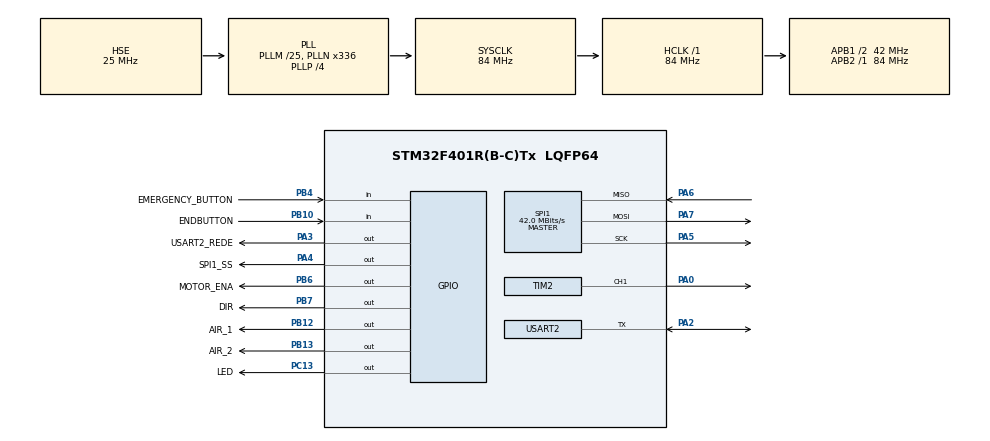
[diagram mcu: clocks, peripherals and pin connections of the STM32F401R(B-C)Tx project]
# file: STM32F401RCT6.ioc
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Dma.Request0=SPI1_RX
Dma.Request1=SPI1_TX
Dma.Request2=USART2_RX
Dma.Request3=USART2_TX
Dma.SPI1_RX.0.Direction=DMA_PERIPH_TO_MEMORY
Dma.SPI1_RX.0.FIFOMode=DMA_FIFOMODE_DISABLE
Dma.SPI1_RX.0.Instance=DMA2_Stream0
Dma.SPI1_RX.0.MemDataAlignment=DMA_MDATAALIGN_BYTE
Dma.SPI1_RX.0.MemInc=DMA_MINC_ENABLE
Dma.SPI1_RX.0.Mode=DMA_NORMAL
Dma.SPI1_RX.0.PeriphDataAlignment=DMA_PDATAALIGN_BYTE
Dma.SPI1_RX.0.PeriphInc=DMA_PINC_DISABLE
Dma.SPI1_RX.0.Priority=DMA_PRIORITY_LOW
Dma.SPI1_TX.1.Direction=DMA_MEMORY_TO_PERIPH
Dma.SPI1_TX.1.FIFOMode=DMA_FIFOMODE_DISABLE
Dma.SPI1_TX.1.Instance=DMA2_Stream3
Dma.SPI1_TX.1.MemDataAlignment=DMA_MDATAALIGN_BYTE
Dma.SPI1_TX.1.MemInc=DMA_MINC_ENABLE
Dma.SPI1_TX.1.Mode=DMA_NORMAL
Dma.SPI1_TX.1.PeriphDataAlignment=DMA_PDATAALIGN_BYTE
Dma.SPI1_TX.1.PeriphInc=DMA_PINC_DISABLE
Dma.SPI1_TX.1.Priority=DMA_PRIORITY_LOW
Dma.USART2_RX.2.Direction=DMA_PERIPH_TO_MEMORY
Dma.USART2_RX.2.FIFOMode=DMA_FIFOMODE_DISABLE
Dma.USART2_RX.2.Instance=DMA1_Stream5
Dma.USART2_RX.2.MemDataAlignment=DMA_MDATAALIGN_BYTE
Dma.USART2_RX.2.MemInc=DMA_MINC_ENABLE
Dma.USART2_RX.2.Mode=DMA_NORMAL
Dma.USART2_RX.2.PeriphDataAlignment=DMA_PDATAALIGN_BYTE
Dma.USART2_RX.2.PeriphInc=DMA_PINC_DISABLE
Dma.USART2_RX.2.Priority=DMA_PRIORITY_LOW
Dma.USART2_TX.3.Direction=DMA_MEMORY_TO_PERIPH
Dma.USART2_TX.3.FIFOMode=DMA_FIFOMODE_DISABLE
Dma.USART2_TX.3.Instance=DMA1_Stream6
Dma.USART2_TX.3.MemDataAlignment=DMA_MDATAALIGN_BYTE
Dma.USART2_TX.3.MemInc=DMA_MINC_ENABLE
Dma.USART2_TX.3.Mode=DMA_NORMAL
Dma.USART2_TX.3.PeriphDataAlignment=DMA_PDATAALIGN_BYTE
Dma.USART2_TX.3.PeriphInc=DMA_PINC_DISABLE
Dma.USART2_TX.3.Priority=DMA_PRIORITY_LOW
FREERTOS.HEAP_NUMBER=1
FREERTOS.Tasks01=defaultTask,24,128,StartCommTask,As weak,NULL,Dynamic,NULL,NULL
FREERTOS.configENABLE_FPU=1
Mcu.Family=STM32F4
Mcu.Name=STM32F401R(B-C)Tx
Mcu.Package=LQFP64
NVIC.DMA1_Stream5_IRQn=true\:5\:0\:false\:false\:true\:true\:false\:true\:true
NVIC.DMA1_Stream6_IRQn=true\:5\:0\:false\:false\:true\:true\:false\:true\:true
NVIC.DMA2_Stream0_IRQn=true\:5\:0\:false\:false\:true\:true\:false\:true\:true
NVIC.DMA2_Stream3_IRQn=true\:5\:0\:false\:false\:true\:true\:false\:true\:true
NVIC.PriorityGroup=NVIC_PRIORITYGROUP_4
NVIC.TIM1_BRK_TIM9_IRQn=true\:5\:0\:false\:false\:true\:true\:true\:true\:true
NVIC.TIM1_TRG_COM_TIM11_IRQn=true\:15\:0\:false\:false\:true\:false\:false\:true\:true
NVIC.TimeBase=TIM1_TRG_COM_TIM11_IRQn
NVIC.TimeBaseIP=TIM11
NVIC.USART2_IRQn=true\:5\:0\:false\:false\:true\:true\:true\:true\:true
PA0-WKUP.GPIO_ModeDefaultPP=GPIO_MODE_AF_OD
PA0-WKUP.GPIO_Speed=GPIO_SPEED_FREQ_VERY_HIGH
PA0-WKUP.Signal=S_TIM2_CH1_ETR
PA13.Mode=Trace_Asynchronous_SW
PA13.Signal=SYS_JTMS-SWDIO
PA14.Mode=Trace_Asynchronous_SW
PA14.Signal=SYS_JTCK-SWCLK
PA2.GPIO_PuPd=GPIO_PULLUP
PA2.Mode=Half_duplex(single_wire_mode)
PA2.Signal=USART2_TX
PA3.GPIO_Label=USART2_REDE
PA3.Signal=GPIO_Output
PA4.GPIO_Label=SPI1_SS
PA4.Signal=GPIO_Output
PA5.Mode=Full_Duplex_Master
PA5.Signal=SPI1_SCK
PA6.Mode=Full_Duplex_Master
PA6.Signal=SPI1_MISO
PA7.Mode=Full_Duplex_Master
PA7.Signal=SPI1_MOSI
PB10.GPIO_Label=ENDBUTTON
PB10.Signal=GPIO_Input
PB12.GPIO_Label=AIR_1
PB12.Signal=GPIO_Output
PB13.GPIO_Label=AIR_2
PB13.Signal=GPIO_Output
PB3.Mode=Trace_Asynchronous_SW
PB3.Signal=SYS_JTDO-SWO
PB4.GPIO_Label=EMERGENCY_BUTTON
PB4.Signal=GPIO_Input
PB6.GPIO_Label=MOTOR_ENA
PB6.GPIO_ModeDefaultOutputPP=GPIO_MODE_OUTPUT_OD
PB6.GPIO_PuPd=GPIO_NOPULL
PB6.Signal=GPIO_Output
PB7.GPIO_Label=DIR
PB7.GPIO_ModeDefaultOutputPP=GPIO_MODE_OUTPUT_OD
PB7.GPIO_PuPd=GPIO_NOPULL
PB7.Signal=GPIO_Output
PC13-ANTI_TAMP.GPIO_Label=LED
PC13-ANTI_TAMP.PinState=GPIO_PIN_RESET
PC13-ANTI_TAMP.Signal=GPIO_Output
PC14-OSC32_IN.Mode=LSE-External-Oscillator
PC14-OSC32_IN.Signal=RCC_OSC32_IN
PC15-OSC32_OUT.Mode=LSE-External-Oscillator
PC15-OSC32_OUT.Signal=RCC_OSC32_OUT
PH0\ -\ OSC_IN.Mode=HSE-External-Oscillator
PH0\ -\ OSC_IN.Signal=RCC_OSC_IN
PH1\ -\ OSC_OUT.Mode=HSE-External-Oscillator
PH1\ -\ OSC_OUT.Signal=RCC_OSC_OUT
ProjectManager.HeapSize=0x200
ProjectManager.StackSize=0x400
ProjectManager.TargetToolchain=CMake
RCC.48MHZClocksFreq_Value=84000000
RCC.AHBFreq_Value=84000000
RCC.APB1CLKDivider=RCC_HCLK_DIV2
RCC.APB1Freq_Value=42000000
RCC.APB1TimFreq_Value=84000000
RCC.APB2Freq_Value=84000000
RCC.APB2TimFreq_Value=84000000
RCC.CortexFreq_Value=84000000
RCC.HCLKFreq_Value=84000000
RCC.HSE_VALUE=25000000
RCC.HSI_VALUE=16000000
RCC.PLLM=25
RCC.PLLN=336
RCC.PLLP=RCC_PLLP_DIV4
RCC.PLLSourceVirtual=RCC_PLLSOURCE_HSE
RCC.SYSCLKFreq_VALUE=84000000
RCC.SYSCLKSource=RCC_SYSCLKSOURCE_PLLCLK
RCC.VCOOutputFreq_Value=336000000
SH.S_TIM2_CH1_ETR.0=TIM2_CH1,Output Compare1 CH1
SPI1.BaudRatePrescaler=SPI_BAUDRATEPRESCALER_2
SPI1.CalculateBaudRate=42.0 MBits/s
SPI1.Direction=SPI_DIRECTION_2LINES
SPI1.Mode=SPI_MODE_MASTER
SPI1.VirtualType=VM_MASTER
TIM2.AutoReloadPreload=TIM_AUTORELOAD_PRELOAD_DISABLE
TIM2.Channel-Output\ Compare1\ CH1=TIM_CHANNEL_1
TIM2.CounterMode=TIM_COUNTERMODE_DOWN
TIM2.OCMode_1=TIM_OCMODE_TOGGLE
TIM2.Period=65535
TIM2.TIM_MasterOutputTrigger=TIM_TRGO_UPDATE
USART2.VirtualMode=VM_ASYNC
VP_FREERTOS_VS_CMSIS_V2.Mode=CMSIS_V2
VP_RTC_VS_RTC_Activate.Mode=RTC_Enabled
VP_SYS_VS_tim11.Mode=TIM11
VP_TIM2_VS_ClockSourceINT.Mode=Internal
VP_TIM9_VS_ClockSourceITR.Mode=TriggerSource_ITR0
VP_TIM9_VS_ControllerModeClock.Mode=Clock Mode
board=custom

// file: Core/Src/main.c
/* USER CODE BEGIN Header */
/**
  ******************************************************************************
  * @file           : main.c
  * @brief          : Main program body
  ******************************************************************************
  * @attention
  *
  * Copyright (c) 2026 STMicroelectronics.
  * All rights reserved.
  *
  * This software is licensed under terms that can be found in the LICENSE file
  * in the root directory of this software component.
  * If no LICENSE file comes with this software, it is provided AS-IS.
  *
  ******************************************************************************
  */
/* USER CODE END Header */
#include "main.h"
#include "cmsis_os.h"

/* USER CODE BEGIN Includes */
#include "acceleration.h"
#include "debug.h"
/* USER CODE END Includes */

RTC_HandleTypeDef hrtc;

SPI_HandleTypeDef hspi1;
DMA_HandleTypeDef hdma_spi1_rx;
DMA_HandleTypeDef hdma_spi1_tx;

TIM_HandleTypeDef htim2;
TIM_HandleTypeDef htim9;

UART_HandleTypeDef huart2;
DMA_HandleTypeDef hdma_usart2_rx;
DMA_HandleTypeDef hdma_usart2_tx;

/* Definitions for defaultTask */
osThreadId_t defaultTaskHandle;
const osThreadAttr_t defaultTask_attributes = {
  .name = "defaultTask",
  .stack_size = 128 * 4,
  .priority = (osPriority_t) osPriorityNormal,
};

void SystemClock_Config(void);
static void MX_GPIO_Init(void);
static void MX_DMA_Init(void);
static void MX_TIM2_Init(void);
static void MX_SPI1_Init(void);
static void MX_USART2_UART_Init(void);
static void MX_TIM9_Init(void);
static void MX_RTC_Init(void);
void StartCommTask(void *argument);

/* USER CODE BEGIN PFP */
void init_communication(void);
/* USER CODE END PFP */

int main(void)
{

  /* MCU Configuration--------------------------------------------------------*/

  /* Reset of all peripherals, Initializes the Flash interface and the Systick. */
  HAL_Init();

  /* Configure the system clock */
  SystemClock_Config();

  /* USER CODE BEGIN SysInit */
  //SWO_Init();
  /* USER CODE END SysInit */

  /* Initialize all configured peripherals */
  MX_GPIO_Init();
  MX_DMA_Init();
  MX_TIM2_Init();
  MX_SPI1_Init();
  MX_USART2_UART_Init();
  MX_TIM9_Init();
  MX_RTC_Init();
  /* USER CODE BEGIN 2 */
  initPositioning();
  init_communication();
  /* USER CODE END 2 */

  /* Init scheduler */
  osKernelInitialize();

  /* Create the thread(s) */
  /* creation of defaultTask */
  defaultTaskHandle = osThreadNew(StartCommTask, NULL, &defaultTask_attributes);

  /* Start scheduler */
  osKernelStart();

  /* We should never get here as control is now taken by the scheduler */

  /* Infinite loop */
  while (1)
  {

  }
}

void SystemClock_Config(void)
{
  RCC_OscInitTypeDef RCC_OscInitStruct = {0};
  RCC_ClkInitTypeDef RCC_ClkInitStruct = {0};

  /** Configure the main internal regulator output voltage
  */
  __HAL_RCC_PWR_CLK_ENABLE();
  __HAL_PWR_VOLTAGESCALING_CONFIG(PWR_REGULATOR_VOLTAGE_SCALE2);

  /** Initializes the RCC Oscillators according to the specified parameters
  * in the RCC_OscInitTypeDef structure.
  */
  RCC_OscInitStruct.OscillatorType = RCC_OSCILLATORTYPE_LSI|RCC_OSCILLATORTYPE_HSE;
  RCC_OscInitStruct.HSEState = RCC_HSE_ON;
  RCC_OscInitStruct.LSIState = RCC_LSI_ON;
  RCC_OscInitStruct.PLL.PLLState = RCC_PLL_ON;
  RCC_OscInitStruct.PLL.PLLSource = RCC_PLLSOURCE_HSE;
  RCC_OscInitStruct.PLL.PLLM = 25;
  RCC_OscInitStruct.PLL.PLLN = 336;
  RCC_OscInitStruct.PLL.PLLP = RCC_PLLP_DIV4;
  RCC_OscInitStruct.PLL.PLLQ = 4;
  if (HAL_RCC_OscConfig(&RCC_OscInitStruct) != HAL_OK)
  {
    Error_Handler();
  }

  /** Initializes the CPU, AHB and APB buses clocks
  */
  RCC_ClkInitStruct.ClockType = RCC_CLOCKTYPE_HCLK|RCC_CLOCKTYPE_SYSCLK
                              |RCC_CLOCKTYPE_PCLK1|RCC_CLOCKTYPE_PCLK2;
  RCC_ClkInitStruct.SYSCLKSource = RCC_SYSCLKSOURCE_PLLCLK;
  RCC_ClkInitStruct.AHBCLKDivider = RCC_SYSCLK_DIV1;
  RCC_ClkInitStruct.APB1CLKDivider = RCC_HCLK_DIV2;
  RCC_ClkInitStruct.APB2CLKDivider = RCC_HCLK_DIV1;

  if (HAL_RCC_ClockConfig(&RCC_ClkInitStruct, FLASH_LATENCY_2) != HAL_OK)
  {
    Error_Handler();
  }
}

static void MX_RTC_Init(void)
{

  /** Initialize RTC Only
  */
  hrtc.Instance = RTC;
  hrtc.Init.HourFormat = RTC_HOURFORMAT_24;
  hrtc.Init.AsynchPrediv = 127;
  hrtc.Init.SynchPrediv = 255;
  hrtc.Init.OutPut = RTC_OUTPUT_DISABLE;
  hrtc.Init.OutPutPolarity = RTC_OUTPUT_POLARITY_HIGH;
  hrtc.Init.OutPutType = RTC_OUTPUT_TYPE_OPENDRAIN;
  if (HAL_RTC_Init(&hrtc) != HAL_OK)
  {
    Error_Handler();
  }

}

static void MX_SPI1_Init(void)
{

  /* SPI1 parameter configuration*/
  hspi1.Instance = SPI1;
  hspi1.Init.Mode = SPI_MODE_MASTER;
  hspi1.Init.Direction = SPI_DIRECTION_2LINES;
  hspi1.Init.DataSize = SPI_DATASIZE_8BIT;
  hspi1.Init.CLKPolarity = SPI_POLARITY_LOW;
  hspi1.Init.CLKPhase = SPI_PHASE_1EDGE;
  hspi1.Init.NSS = SPI_NSS_SOFT;
  hspi1.Init.BaudRatePrescaler = SPI_BAUDRATEPRESCALER_2;
  hspi1.Init.FirstBit = SPI_FIRSTBIT_MSB;
  hspi1.Init.TIMode = SPI_TIMODE_DISABLE;
  hspi1.Init.CRCCalculation = SPI_CRCCALCULATION_DISABLE;
  hspi1.Init.CRCPolynomial = 10;
  if (HAL_SPI_Init(&hspi1) != HAL_OK)
  {
    Error_Handler();
  }

}

static void MX_TIM2_Init(void)
{

  TIM_ClockConfigTypeDef sClockSourceConfig = {0};
  TIM_MasterConfigTypeDef sMasterConfig = {0};
  TIM_OC_InitTypeDef sConfigOC = {0};

  htim2.Instance = TIM2;
  htim2.Init.Prescaler = 0;
  htim2.Init.CounterMode = TIM_COUNTERMODE_DOWN;
  htim2.Init.Period = 65535;
  htim2.Init.ClockDivision = TIM_CLOCKDIVISION_DIV1;
  htim2.Init.AutoReloadPreload = TIM_AUTORELOAD_PRELOAD_DISABLE;
  if (HAL_TIM_Base_Init(&htim2) != HAL_OK)
  {
    Error_Handler();
  }
  sClockSourceConfig.ClockSource = TIM_CLOCKSOURCE_INTERNAL;
  if (HAL_TIM_ConfigClockSource(&htim2, &sClockSourceConfig) != HAL_OK)
  {
    Error_Handler();
  }
  if (HAL_TIM_OC_Init(&htim2) != HAL_OK)
  {
    Error_Handler();
  }
  sMasterConfig.MasterOutputTrigger = TIM_TRGO_UPDATE;
  sMasterConfig.MasterSlaveMode = TIM_MASTERSLAVEMODE_DISABLE;
  if (HAL_TIMEx_MasterConfigSynchronization(&htim2, &sMasterConfig) != HAL_OK)
  {
    Error_Handler();
  }
  sConfigOC.OCMode = TIM_OCMODE_TOGGLE;
  sConfigOC.Pulse = 0;
  sConfigOC.OCPolarity = TIM_OCPOLARITY_HIGH;
  sConfigOC.OCFastMode = TIM_OCFAST_DISABLE;
  if (HAL_TIM_OC_ConfigChannel(&htim2, &sConfigOC, TIM_CHANNEL_1) != HAL_OK)
  {
    Error_Handler();
  }
  HAL_TIM_MspPostInit(&htim2);

}

static void MX_TIM9_Init(void)
{

  TIM_SlaveConfigTypeDef sSlaveConfig = {0};

  htim9.Instance = TIM9;
  htim9.Init.Prescaler = 0;
  htim9.Init.CounterMode = TIM_COUNTERMODE_UP;
  htim9.Init.Period = 65535;
  htim9.Init.ClockDivision = TIM_CLOCKDIVISION_DIV1;
  htim9.Init.AutoReloadPreload = TIM_AUTORELOAD_PRELOAD_DISABLE;
  if (HAL_TIM_Base_Init(&htim9) != HAL_OK)
  {
    Error_Handler();
  }
  sSlaveConfig.SlaveMode = TIM_SLAVEMODE_EXTERNAL1;
  sSlaveConfig.InputTrigger = TIM_TS_ITR0;
  if (HAL_TIM_SlaveConfigSynchro(&htim9, &sSlaveConfig) != HAL_OK)
  {
    Error_Handler();
  }

}

static void MX_USART2_UART_Init(void)
{

  huart2.Instance = USART2;
  huart2.Init.BaudRate = 115200;
  huart2.Init.WordLength = UART_WORDLENGTH_8B;
  huart2.Init.StopBits = UART_STOPBITS_1;
  huart2.Init.Parity = UART_PARITY_NONE;
  huart2.Init.Mode = UART_MODE_TX_RX;
  huart2.Init.HwFlowCtl = UART_HWCONTROL_NONE;
  huart2.Init.OverSampling = UART_OVERSAMPLING_16;
  if (HAL_HalfDuplex_Init(&huart2) != HAL_OK)
  {
    Error_Handler();
  }

}

static void MX_DMA_Init(void)
{

  /* DMA controller clock enable */
  __HAL_RCC_DMA2_CLK_ENABLE();
  __HAL_RCC_DMA1_CLK_ENABLE();

  /* DMA interrupt init */
  /* DMA1_Stream5_IRQn interrupt configuration */
  HAL_NVIC_SetPriority(DMA1_Stream5_IRQn, 5, 0);
  HAL_NVIC_EnableIRQ(DMA1_Stream5_IRQn);
  /* DMA1_Stream6_IRQn interrupt configuration */
  HAL_NVIC_SetPriority(DMA1_Stream6_IRQn, 5, 0);
  HAL_NVIC_EnableIRQ(DMA1_Stream6_IRQn);
  /* DMA2_Stream0_IRQn interrupt configuration */
  HAL_NVIC_SetPriority(DMA2_Stream0_IRQn, 5, 0);
  HAL_NVIC_EnableIRQ(DMA2_Stream0_IRQn);
  /* DMA2_Stream3_IRQn interrupt configuration */
  HAL_NVIC_SetPriority(DMA2_Stream3_IRQn, 5, 0);
  HAL_NVIC_EnableIRQ(DMA2_Stream3_IRQn);

}

static void MX_GPIO_Init(void)
{
  GPIO_InitTypeDef GPIO_InitStruct = {0};

  /* GPIO Ports Clock Enable */
  __HAL_RCC_GPIOC_CLK_ENABLE();
  __HAL_RCC_GPIOH_CLK_ENABLE();
  __HAL_RCC_GPIOA_CLK_ENABLE();
  __HAL_RCC_GPIOB_CLK_ENABLE();

  /*Configure GPIO pin Output Level */
  HAL_GPIO_WritePin(LED_GPIO_Port, LED_Pin, GPIO_PIN_RESET);

  /*Configure GPIO pin Output Level */
  HAL_GPIO_WritePin(GPIOA, USART2_REDE_Pin|SPI1_SS_Pin, GPIO_PIN_RESET);

  /*Configure GPIO pin Output Level */
  HAL_GPIO_WritePin(GPIOB, AIR_1_Pin|AIR_2_Pin|MOTOR_ENA_Pin|DIR_Pin, GPIO_PIN_RESET);

  /*Configure GPIO pin : LED_Pin */
  GPIO_InitStruct.Pin = LED_Pin;
  GPIO_InitStruct.Mode = GPIO_MODE_OUTPUT_PP;
  GPIO_InitStruct.Pull = GPIO_NOPULL;
  GPIO_InitStruct.Speed = GPIO_SPEED_FREQ_LOW;
  HAL_GPIO_Init(LED_GPIO_Port, &GPIO_InitStruct);

  /*Configure GPIO pins : USART2_REDE_Pin SPI1_SS_Pin */
  GPIO_InitStruct.Pin = USART2_REDE_Pin|SPI1_SS_Pin;
  GPIO_InitStruct.Mode = GPIO_MODE_OUTPUT_PP;
  GPIO_InitStruct.Pull = GPIO_NOPULL;
  GPIO_InitStruct.Speed = GPIO_SPEED_FREQ_LOW;
  HAL_GPIO_Init(GPIOA, &GPIO_InitStruct);

  /*Configure GPIO pins : ENDBUTTON_Pin EMERGENCY_BUTTON_Pin */
  GPIO_InitStruct.Pin = ENDBUTTON_Pin|EMERGENCY_BUTTON_Pin;
  GPIO_InitStruct.Mode = GPIO_MODE_INPUT;
  GPIO_InitStruct.Pull = GPIO_NOPULL;
  HAL_GPIO_Init(GPIOB, &GPIO_InitStruct);

  /*Configure GPIO pins : AIR_1_Pin AIR_2_Pin */
  GPIO_InitStruct.Pin = AIR_1_Pin|AIR_2_Pin;
  GPIO_InitStruct.Mode = GPIO_MODE_OUTPUT_PP;
  GPIO_InitStruct.Pull = GPIO_NOPULL;
  GPIO_InitStruct.Speed = GPIO_SPEED_FREQ_LOW;
  HAL_GPIO_Init(GPIOB, &GPIO_InitStruct);

  /*Configure GPIO pins : MOTOR_ENA_Pin DIR_Pin */
  GPIO_InitStruct.Pin = MOTOR_ENA_Pin|DIR_Pin;
  GPIO_InitStruct.Mode = GPIO_MODE_OUTPUT_OD;
  GPIO_InitStruct.Pull = GPIO_NOPULL;
  GPIO_InitStruct.Speed = GPIO_SPEED_FREQ_LOW;
  HAL_GPIO_Init(GPIOB, &GPIO_InitStruct);

}

__weak void StartCommTask(void *argument)
{
  for(;;)
  {
  }
}

void HAL_TIM_PeriodElapsedCallback(TIM_HandleTypeDef *htim)
{
  /* USER CODE BEGIN Callback 0 */
  if (htim->Instance == TIM9)
  {
    processPositionCounter();
  }
  if (htim->Instance == TIM11)
  {
    processAcceleration();
  }
  /* USER CODE END Callback 0 */
  if (htim->Instance == TIM11)
  {
    HAL_IncTick();
  }
}

void Error_Handler(void)
{
  /* USER CODE BEGIN Error_Handler_Debug */
  /* User can add his own implementation to report the HAL error return state */
  __disable_irq();
  while (1)
  {
    //puts("HAL error!");
  }
  /* USER CODE END Error_Handler_Debug */
}
